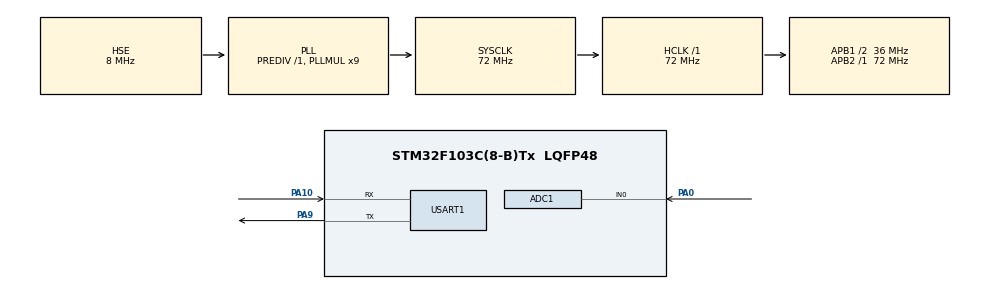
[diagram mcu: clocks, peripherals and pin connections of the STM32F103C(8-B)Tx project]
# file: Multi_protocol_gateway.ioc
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ADC1.Channel-0\#ChannelRegularConversion=ADC_CHANNEL_0
ADC1.ExternalTrigConv=ADC_EXTERNALTRIGCONV_T3_TRGO
ADC1.NbrOfConversionFlag=1
ADC1.Rank-0\#ChannelRegularConversion=1
ADC1.SamplingTime-0\#ChannelRegularConversion=ADC_SAMPLETIME_239CYCLES_5
ADC1.master=1
Dma.ADC1.0.Direction=DMA_PERIPH_TO_MEMORY
Dma.ADC1.0.Instance=DMA1_Channel1
Dma.ADC1.0.MemDataAlignment=DMA_MDATAALIGN_HALFWORD
Dma.ADC1.0.MemInc=DMA_MINC_ENABLE
Dma.ADC1.0.Mode=DMA_CIRCULAR
Dma.ADC1.0.PeriphDataAlignment=DMA_PDATAALIGN_HALFWORD
Dma.ADC1.0.PeriphInc=DMA_PINC_DISABLE
Dma.ADC1.0.Priority=DMA_PRIORITY_MEDIUM
Dma.Request0=ADC1
Dma.Request1=USART1_TX
Dma.USART1_TX.1.Direction=DMA_MEMORY_TO_PERIPH
Dma.USART1_TX.1.Instance=DMA1_Channel4
Dma.USART1_TX.1.MemDataAlignment=DMA_MDATAALIGN_BYTE
Dma.USART1_TX.1.MemInc=DMA_MINC_ENABLE
Dma.USART1_TX.1.Mode=DMA_NORMAL
Dma.USART1_TX.1.PeriphDataAlignment=DMA_PDATAALIGN_BYTE
Dma.USART1_TX.1.PeriphInc=DMA_PINC_DISABLE
Dma.USART1_TX.1.Priority=DMA_PRIORITY_MEDIUM
Mcu.Family=STM32F1
Mcu.Name=STM32F103C(8-B)Tx
Mcu.Package=LQFP48
NVIC.DMA1_Channel1_IRQn=true\:0\:0\:false\:false\:true\:false\:true\:true
NVIC.DMA1_Channel4_IRQn=true\:0\:0\:false\:false\:true\:false\:true\:true
NVIC.PriorityGroup=NVIC_PRIORITYGROUP_4
NVIC.USART1_IRQn=true\:0\:0\:false\:false\:true\:false\:true\:true
PA0-WKUP.Signal=ADCx_IN0
PA10.Mode=Asynchronous
PA10.Signal=USART1_RX
PA13.Mode=Serial_Wire
PA13.Signal=SYS_JTMS-SWDIO
PA14.Mode=Serial_Wire
PA14.Signal=SYS_JTCK-SWCLK
PA9.Mode=Asynchronous
PA9.Signal=USART1_TX
PD0-OSC_IN.Mode=HSE-External-Oscillator
PD0-OSC_IN.Signal=RCC_OSC_IN
PD1-OSC_OUT.Mode=HSE-External-Oscillator
PD1-OSC_OUT.Signal=RCC_OSC_OUT
ProjectManager.HeapSize=0x200
ProjectManager.StackSize=0x400
ProjectManager.TargetToolchain=STM32CubeIDE
RCC.ADCPresc=RCC_ADCPCLK2_DIV6
RCC.AHBFreq_Value=72000000
RCC.APB1CLKDivider=RCC_HCLK_DIV2
RCC.APB1Freq_Value=36000000
RCC.APB1TimFreq_Value=72000000
RCC.APB2Freq_Value=72000000
RCC.APB2TimFreq_Value=72000000
RCC.HCLKFreq_Value=72000000
RCC.PLLMUL=RCC_PLL_MUL9
RCC.PLLSourceVirtual=RCC_PLLSOURCE_HSE
RCC.SYSCLKFreq_VALUE=72000000
RCC.SYSCLKSource=RCC_SYSCLKSOURCE_PLLCLK
RCC.USBFreq_Value=72000000
SH.ADCx_IN0.0=ADC1_IN0,IN0
TIM3.Period=9
TIM3.Prescaler=7199
TIM3.TIM_MasterOutputTrigger=TIM_TRGO_UPDATE
USART1.VirtualMode=VM_ASYNC
VP_TIM3_VS_ClockSourceINT.Mode=Internal
board=custom

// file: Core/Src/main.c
/* USER CODE BEGIN Header */
/**
  ******************************************************************************
  * @file           : main.c
  * @brief          : Main program body
  ******************************************************************************
  * @attention
  *
  * Copyright (c) 2026 STMicroelectronics.
  * All rights reserved.
  *
  * This software is licensed under terms that can be found in the LICENSE file
  * in the root directory of this software component.
  * If no LICENSE file comes with this software, it is provided AS-IS.
  *
  ******************************************************************************
  */
/* USER CODE END Header */
#include "main.h"

/* USER CODE BEGIN Includes */
#include <stdio.h>
#include <stdlib.h>
#include <string.h>
/* USER CODE END Includes */

ADC_HandleTypeDef hadc1;
DMA_HandleTypeDef hdma_adc1;

TIM_HandleTypeDef htim3;

UART_HandleTypeDef huart1;
DMA_HandleTypeDef hdma_usart1_tx;

/* USER CODE BEGIN PV */

#define ADC_BUF_LEN 200
uint16_t adc_buf[ADC_BUF_LEN];

volatile uint8_t adc_half_ready = 0;
volatile uint8_t adc_full_ready = 0;

// USART1 TX via DMA
static volatile uint8_t uart_tx_busy = 0;

static uint8_t tx_buf_a[64];
static uint8_t tx_buf_b[64];
static volatile uint8_t *tx_active = tx_buf_a;
static volatile uint8_t *tx_queued = NULL;
static volatile uint16_t tx_queued_len = 0;

static uint16_t seq_counter = 0;

/* USER CODE END PV */

void SystemClock_Config(void);
static void MX_GPIO_Init(void);
static void MX_DMA_Init(void);
static void MX_ADC1_Init(void);
static void MX_TIM3_Init(void);
static void MX_USART1_UART_Init(void);

/* USER CODE BEGIN 0 */

static uint16_t avg_u16(const uint16_t *p, int n)
{
  uint32_t sum = 0;
  for (int i = 0; i < n; i++) sum += p[i];
  return (uint16_t)(sum / (uint32_t)n);
}

static uint16_t iir_u16(uint16_t prev, uint16_t sample, uint8_t shift)
{
  int32_t diff = (int32_t)sample - (int32_t)prev;
  return (uint16_t)((int32_t)prev + (diff >> shift));  // alpha=1/2^shift
}

static int16_t lm35_temp_c_x100_from_adc(uint16_t adc_counts)
{
  const int32_t vref_mv = 3300;
  int32_t mv = (int32_t)adc_counts * vref_mv / 4095;
  int32_t temp_c_x100 = (mv * 100) / 10;   // 10mV/°C
  return (int16_t)temp_c_x100;
}

#define PKT_MAGIC   0xAA55
#define PKT_VERSION 1
#define MSG_TELEMETRY 0x01

static uint16_t crc16_ccitt(const uint8_t *data, uint32_t len)
{
  uint16_t crc = 0xFFFF;
  for (uint32_t i = 0; i < len; i++)
  {
    crc ^= (uint16_t)data[i] << 8;
    for (int b = 0; b < 8; b++)
    {
      if (crc & 0x8000) crc = (crc << 1) ^ 0x1021;
      else             crc = (crc << 1);
    }
  }
  return crc;
}

static void wr_le16(uint8_t *p, uint16_t v)
{
  p[0] = (uint8_t)(v & 0xFF);
  p[1] = (uint8_t)(v >> 8);
}

static void wr_le32(uint8_t *p, uint32_t v)
{
  p[0] = (uint8_t)(v & 0xFF);
  p[1] = (uint8_t)(v >> 8);
  p[2] = (uint8_t)(v >> 16);
  p[3] = (uint8_t)(v >> 24);
}

static void uart1_send_frame_dma(uint8_t *frame, uint16_t len)
{
  if (len == 0) return;

  if (!uart_tx_busy)
  {
    uart_tx_busy = 1;
    tx_active = frame;
    HAL_UART_Transmit_DMA(&huart1, frame, len);
  }
  else
  {
    // queue 1 frame (simple). If already queued, drop newest.
    if (tx_queued == NULL)
    {
      tx_queued = frame;
      tx_queued_len = len;
    }
  }
}

/* USER CODE END 0 */

int main(void)
{

  /* MCU Configuration--------------------------------------------------------*/

  /* Reset of all peripherals, Initializes the Flash interface and the Systick. */
  HAL_Init();

  /* Configure the system clock */
  SystemClock_Config();

  /* Initialize all configured peripherals */
  MX_GPIO_Init();
  MX_DMA_Init();
  MX_ADC1_Init();
  MX_TIM3_Init();
  MX_USART1_UART_Init();
  /* USER CODE BEGIN 2 */

  HAL_TIM_Base_Start(&htim3);

  // Recommended on STM32F1
  HAL_ADCEx_Calibration_Start(&hadc1);

  HAL_ADC_Start_DMA(&hadc1, (uint32_t*)adc_buf, ADC_BUF_LEN);

  /* USER CODE END 2 */

  /* Infinite loop */
  while (1)
  {

	    static uint16_t filt_adc = 0;
	    static uint8_t  filt_init = 0;

	    uint8_t  updated = 0;
	    uint16_t avg = 0;

	    if (adc_half_ready)
	    {
	      adc_half_ready = 0;
	      avg = avg_u16(&adc_buf[0], ADC_BUF_LEN/2);
	      updated = 1;
	    }

	    if (adc_full_ready)
	    {
	      adc_full_ready = 0;
	      avg = avg_u16(&adc_buf[ADC_BUF_LEN/2], ADC_BUF_LEN/2);
	      updated = 1;
	    }

	    if (updated)
	    {
	      // ---- IIR filter on averaged sample ----
	      if (!filt_init)
	      {
	        filt_adc = avg;
	        filt_init = 1;
	      }
	      else
	      {
	        filt_adc = iir_u16(filt_adc, avg, 3); // alpha = 1/8
	      }

	      int16_t t_x100 = lm35_temp_c_x100_from_adc(filt_adc);

	      // ---- Build binary telemetry packet ----
	      // pick buffer not currently active (ping-pong)
	      uint8_t *buf;

	      if (!uart_tx_busy)
	      {
	        // DMA idle → can use either buffer; use the one not last active
	        buf = (tx_active == tx_buf_a) ? tx_buf_b : tx_buf_a;
	      }
	      else
	      {
	        // DMA busy
	        if (tx_queued == NULL)
	        {
	          // one free buffer remains → use the one not active
	          buf = (tx_active == tx_buf_a) ? tx_buf_b : tx_buf_a;
	        }
	        else
	        {
	          // DMA busy AND one frame already queued → no free buffer
	          // simplest: drop this update
	          continue;
	        }
	      }

	      uint16_t payload_len = 5;
	      uint16_t seq = seq_counter++;
	      uint32_t ts  = HAL_GetTick();

	      // Header (12 bytes)
	      wr_le16(&buf[0], PKT_MAGIC);
	      buf[2] = PKT_VERSION;
	      buf[3] = MSG_TELEMETRY;
	      wr_le16(&buf[4], payload_len);
	      wr_le16(&buf[6], seq);
	      wr_le32(&buf[8], ts);

	      // Payload (5 bytes)
	      wr_le16(&buf[12], (uint16_t)filt_adc);          // raw_adc
	      wr_le16(&buf[14], (uint16_t)(int16_t)t_x100);   // temp_c_x100
	      buf[16] = 0x00;                                 // flags

	      // CRC16 over header+payload
	      uint16_t frame_len_no_crc = 12 + payload_len;
	      uint16_t crc = crc16_ccitt(buf, frame_len_no_crc);
	      wr_le16(&buf[frame_len_no_crc], crc);

	      uint16_t total_len = frame_len_no_crc + 2;

	      // Send via UART DMA (normal mode)
	      uart1_send_frame_dma(buf, total_len);
	    }
  }
}

void SystemClock_Config(void)
{
  RCC_OscInitTypeDef RCC_OscInitStruct = {0};
  RCC_ClkInitTypeDef RCC_ClkInitStruct = {0};
  RCC_PeriphCLKInitTypeDef PeriphClkInit = {0};

  /** Initializes the RCC Oscillators according to the specified parameters
  * in the RCC_OscInitTypeDef structure.
  */
  RCC_OscInitStruct.OscillatorType = RCC_OSCILLATORTYPE_HSE;
  RCC_OscInitStruct.HSEState = RCC_HSE_ON;
  RCC_OscInitStruct.HSEPredivValue = RCC_HSE_PREDIV_DIV1;
  RCC_OscInitStruct.HSIState = RCC_HSI_ON;
  RCC_OscInitStruct.PLL.PLLState = RCC_PLL_ON;
  RCC_OscInitStruct.PLL.PLLSource = RCC_PLLSOURCE_HSE;
  RCC_OscInitStruct.PLL.PLLMUL = RCC_PLL_MUL9;
  if (HAL_RCC_OscConfig(&RCC_OscInitStruct) != HAL_OK)
  {
    Error_Handler();
  }

  /** Initializes the CPU, AHB and APB buses clocks
  */
  RCC_ClkInitStruct.ClockType = RCC_CLOCKTYPE_HCLK|RCC_CLOCKTYPE_SYSCLK
                              |RCC_CLOCKTYPE_PCLK1|RCC_CLOCKTYPE_PCLK2;
  RCC_ClkInitStruct.SYSCLKSource = RCC_SYSCLKSOURCE_PLLCLK;
  RCC_ClkInitStruct.AHBCLKDivider = RCC_SYSCLK_DIV1;
  RCC_ClkInitStruct.APB1CLKDivider = RCC_HCLK_DIV2;
  RCC_ClkInitStruct.APB2CLKDivider = RCC_HCLK_DIV1;

  if (HAL_RCC_ClockConfig(&RCC_ClkInitStruct, FLASH_LATENCY_2) != HAL_OK)
  {
    Error_Handler();
  }
  PeriphClkInit.PeriphClockSelection = RCC_PERIPHCLK_ADC;
  PeriphClkInit.AdcClockSelection = RCC_ADCPCLK2_DIV6;
  if (HAL_RCCEx_PeriphCLKConfig(&PeriphClkInit) != HAL_OK)
  {
    Error_Handler();
  }
}

static void MX_ADC1_Init(void)
{

  ADC_ChannelConfTypeDef sConfig = {0};

  /** Common config
  */
  hadc1.Instance = ADC1;
  hadc1.Init.ScanConvMode = ADC_SCAN_DISABLE;
  hadc1.Init.ContinuousConvMode = DISABLE;
  hadc1.Init.DiscontinuousConvMode = DISABLE;
  hadc1.Init.ExternalTrigConv = ADC_EXTERNALTRIGCONV_T3_TRGO;
  hadc1.Init.DataAlign = ADC_DATAALIGN_RIGHT;
  hadc1.Init.NbrOfConversion = 1;
  if (HAL_ADC_Init(&hadc1) != HAL_OK)
  {
    Error_Handler();
  }

  /** Configure Regular Channel
  */
  sConfig.Channel = ADC_CHANNEL_0;
  sConfig.Rank = ADC_REGULAR_RANK_1;
  sConfig.SamplingTime = ADC_SAMPLETIME_239CYCLES_5;
  if (HAL_ADC_ConfigChannel(&hadc1, &sConfig) != HAL_OK)
  {
    Error_Handler();
  }

}

static void MX_TIM3_Init(void)
{

  TIM_ClockConfigTypeDef sClockSourceConfig = {0};
  TIM_MasterConfigTypeDef sMasterConfig = {0};

  htim3.Instance = TIM3;
  htim3.Init.Prescaler = 7199;
  htim3.Init.CounterMode = TIM_COUNTERMODE_UP;
  htim3.Init.Period = 9;
  htim3.Init.ClockDivision = TIM_CLOCKDIVISION_DIV1;
  htim3.Init.AutoReloadPreload = TIM_AUTORELOAD_PRELOAD_DISABLE;
  if (HAL_TIM_Base_Init(&htim3) != HAL_OK)
  {
    Error_Handler();
  }
  sClockSourceConfig.ClockSource = TIM_CLOCKSOURCE_INTERNAL;
  if (HAL_TIM_ConfigClockSource(&htim3, &sClockSourceConfig) != HAL_OK)
  {
    Error_Handler();
  }
  sMasterConfig.MasterOutputTrigger = TIM_TRGO_UPDATE;
  sMasterConfig.MasterSlaveMode = TIM_MASTERSLAVEMODE_DISABLE;
  if (HAL_TIMEx_MasterConfigSynchronization(&htim3, &sMasterConfig) != HAL_OK)
  {
    Error_Handler();
  }

}

static void MX_USART1_UART_Init(void)
{

  huart1.Instance = USART1;
  huart1.Init.BaudRate = 115200;
  huart1.Init.WordLength = UART_WORDLENGTH_8B;
  huart1.Init.StopBits = UART_STOPBITS_1;
  huart1.Init.Parity = UART_PARITY_NONE;
  huart1.Init.Mode = UART_MODE_TX_RX;
  huart1.Init.HwFlowCtl = UART_HWCONTROL_NONE;
  huart1.Init.OverSampling = UART_OVERSAMPLING_16;
  if (HAL_UART_Init(&huart1) != HAL_OK)
  {
    Error_Handler();
  }

}

static void MX_DMA_Init(void)
{

  /* DMA controller clock enable */
  __HAL_RCC_DMA1_CLK_ENABLE();

  /* DMA interrupt init */
  /* DMA1_Channel1_IRQn interrupt configuration */
  HAL_NVIC_SetPriority(DMA1_Channel1_IRQn, 0, 0);
  HAL_NVIC_EnableIRQ(DMA1_Channel1_IRQn);
  /* DMA1_Channel4_IRQn interrupt configuration */
  HAL_NVIC_SetPriority(DMA1_Channel4_IRQn, 0, 0);
  HAL_NVIC_EnableIRQ(DMA1_Channel4_IRQn);

}

static void MX_GPIO_Init(void)
{

  /* GPIO Ports Clock Enable */
  __HAL_RCC_GPIOD_CLK_ENABLE();
  __HAL_RCC_GPIOA_CLK_ENABLE();

}

/* USER CODE BEGIN 4 */

void HAL_ADC_ConvHalfCpltCallback(ADC_HandleTypeDef* hadc)
{
  if (hadc->Instance == ADC1) adc_half_ready = 1;
}

void HAL_ADC_ConvCpltCallback(ADC_HandleTypeDef* hadc)
{
  if (hadc->Instance == ADC1) adc_full_ready = 1;
}

void HAL_UART_TxCpltCallback(UART_HandleTypeDef *huart)
{
  if (huart->Instance == USART1)
  {
    if (tx_queued)
    {
      volatile uint8_t *p = tx_queued;
      uint16_t l = tx_queued_len;

      tx_queued = NULL;
      tx_queued_len = 0;

      tx_active = p;
      HAL_UART_Transmit_DMA(&huart1, (uint8_t*)p, l);
    }
    else
    {
      uart_tx_busy = 0;
    }
  }
}

/* USER CODE END 4 */

void Error_Handler(void)
{
  __disable_irq();
  while (1)
  {
  }
}
